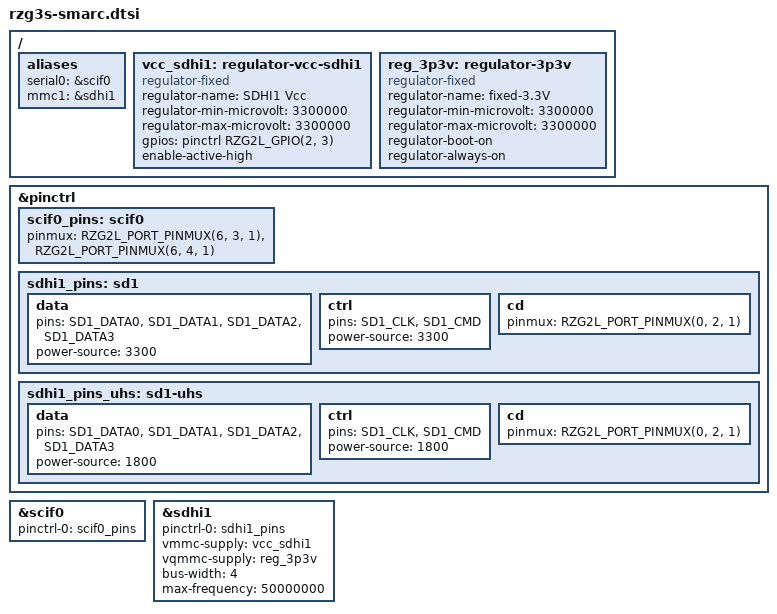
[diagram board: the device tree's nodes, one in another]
// SPDX-License-Identifier: (GPL-2.0-only OR BSD-2-Clause)
/*
 * Device Tree Source for the RZ SMARC Carrier-II Board.
 *
 * Copyright (C) 2023 Renesas Electronics Corp.
 */

#include <dt-bindings/gpio/gpio.h>
#include <dt-bindings/pinctrl/rzg2l-pinctrl.h>

/ {
	aliases {
		serial0 = &scif0;
		mmc1 = &sdhi1;
	};

	vcc_sdhi1: regulator-vcc-sdhi1 {
		compatible = "regulator-fixed";
		regulator-name = "SDHI1 Vcc";
		regulator-min-microvolt = <3300000>;
		regulator-max-microvolt = <3300000>;
		gpios = <&pinctrl RZG2L_GPIO(2, 3) GPIO_ACTIVE_HIGH>;
		enable-active-high;
	};

	reg_3p3v: regulator-3p3v {
		compatible = "regulator-fixed";
		regulator-name = "fixed-3.3V";
		regulator-min-microvolt = <3300000>;
		regulator-max-microvolt = <3300000>;
		regulator-boot-on;
		regulator-always-on;
	};
};

&pinctrl {
	scif0_pins: scif0 {
		pinmux = <RZG2L_PORT_PINMUX(6, 3, 1)>, /* RXD */
			 <RZG2L_PORT_PINMUX(6, 4, 1)>; /* TXD */
	};

	sdhi1_pins: sd1 {
		data {
			pins = "SD1_DATA0", "SD1_DATA1", "SD1_DATA2", "SD1_DATA3";
			power-source = <3300>;
		};

		ctrl {
			pins = "SD1_CLK", "SD1_CMD";
			power-source = <3300>;
		};

		cd {
			pinmux = <RZG2L_PORT_PINMUX(0, 2, 1)>; /* SD1_CD */
		};
	};

	sdhi1_pins_uhs: sd1-uhs {
		data {
			pins = "SD1_DATA0", "SD1_DATA1", "SD1_DATA2", "SD1_DATA3";
			power-source = <1800>;
		};

		ctrl {
			pins = "SD1_CLK", "SD1_CMD";
			power-source = <1800>;
		};

		cd {
			pinmux = <RZG2L_PORT_PINMUX(0, 2, 1)>; /* SD1_CD */
		};
	};
};

&scif0 {
	pinctrl-names = "default";
	pinctrl-0 = <&scif0_pins>;
	status = "okay";
};

&sdhi1 {
	pinctrl-0 = <&sdhi1_pins>;
	pinctrl-names = "default";
	vmmc-supply = <&vcc_sdhi1>;
	vqmmc-supply = <&reg_3p3v>;
	bus-width = <4>;
	max-frequency = <50000000>;
	status = "okay";
};
